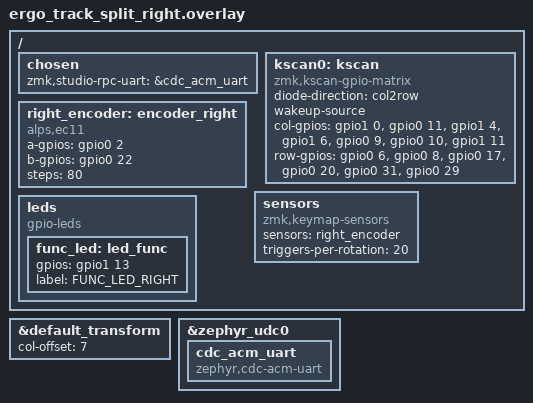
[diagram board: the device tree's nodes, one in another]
/*
 * Copyright (c) 2024
 * SPDX-License-Identifier: MIT
 */

#include "ergo_track_split.dtsi"
#include <zephyr/dt-bindings/input/input-event-codes.h>

&default_transform {
    col-offset = <7>;
};

/ {
    chosen {
        zmk,studio-rpc-uart = &cdc_acm_uart;
    };

    kscan0: kscan {
        compatible = "zmk,kscan-gpio-matrix";
        diode-direction = "col2row";
        wakeup-source;

        col-gpios
            = <&gpio1 0 GPIO_ACTIVE_HIGH>
            , <&gpio0 11 GPIO_ACTIVE_HIGH>
            , <&gpio1 4 GPIO_ACTIVE_HIGH>
            , <&gpio1 6 GPIO_ACTIVE_HIGH>
            , <&gpio0 9 GPIO_ACTIVE_HIGH>
            , <&gpio0 10 GPIO_ACTIVE_HIGH>
            , <&gpio1 11 GPIO_ACTIVE_HIGH>;

        row-gpios
            = <&gpio0 6 (GPIO_ACTIVE_HIGH | GPIO_PULL_DOWN)>
            , <&gpio0 8 (GPIO_ACTIVE_HIGH | GPIO_PULL_DOWN)>
            , <&gpio0 17 (GPIO_ACTIVE_HIGH | GPIO_PULL_DOWN)>
            , <&gpio0 20 (GPIO_ACTIVE_HIGH | GPIO_PULL_DOWN)>
            , <&gpio0 31 (GPIO_ACTIVE_HIGH | GPIO_PULL_DOWN)>
            , <&gpio0 29 (GPIO_ACTIVE_HIGH | GPIO_PULL_DOWN)>;
    };

    right_encoder: encoder_right {
        compatible = "alps,ec11";
        a-gpios = <&gpio0 2 (GPIO_ACTIVE_HIGH | GPIO_PULL_UP)>;
        b-gpios = <&gpio0 22 (GPIO_ACTIVE_HIGH | GPIO_PULL_UP)>;
        steps = <80>;
        status = "okay";
        #sensor-binding-cells = <0>;
    };

    sensors {
        compatible = "zmk,keymap-sensors";
        sensors = <&right_encoder>;
        triggers-per-rotation = <20>;
    };

    leds {
        compatible = "gpio-leds";
        func_led: led_func {
            gpios = <&gpio1 13 GPIO_ACTIVE_HIGH>;
            label = "FUNC_LED_RIGHT";
        };
    };
};

&zephyr_udc0 {
    cdc_acm_uart: cdc_acm_uart {
        compatible = "zephyr,cdc-acm-uart";
    };
};
